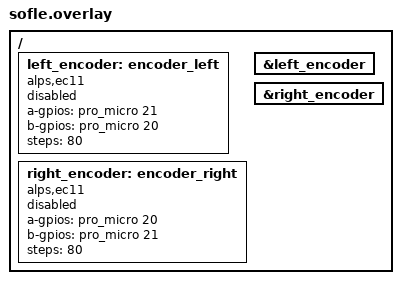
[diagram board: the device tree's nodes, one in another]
/*
 * Copyright (c) 2020 Ryan Cross
 *
 * SPDX-License-Identifier: MIT
 */

#include <dt-bindings/zmk/matrix_transform.h>
#include <physical_layouts.dtsi>
/ {

    left_encoder: encoder_left {
        compatible = "alps,ec11";
        a-gpios = <&pro_micro 21 (GPIO_ACTIVE_HIGH | GPIO_PULL_UP)>;
        b-gpios = <&pro_micro 20 (GPIO_ACTIVE_HIGH | GPIO_PULL_UP)>;
        steps = <80>;
        status = "disabled";
    };

    right_encoder: encoder_right {
        compatible = "alps,ec11";
        a-gpios = <&pro_micro 20 (GPIO_ACTIVE_HIGH | GPIO_PULL_UP)>;
        b-gpios = <&pro_micro 21 (GPIO_ACTIVE_HIGH | GPIO_PULL_UP)>;
        steps = <80>;
        status = "disabled";
    };
    
    &left_encoder {
    status = "okay";
};

&right_encoder {
    status = "okay";
};
};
